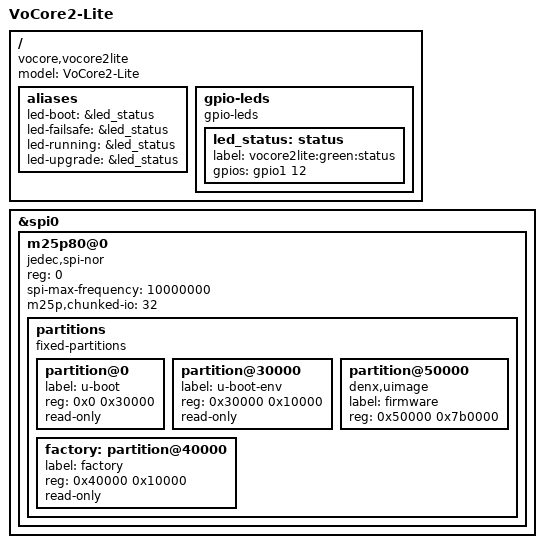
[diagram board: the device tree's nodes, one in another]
/dts-v1/;

#include "VOCORE2.dtsi"

#include <dt-bindings/gpio/gpio.h>

/ {
	compatible = "vocore,vocore2lite", "vocore,vocore2", "mediatek,mt7628an-soc";
	model = "VoCore2-Lite";

	aliases {
		led-boot = &led_status;
		led-failsafe = &led_status;
		led-running = &led_status;
		led-upgrade = &led_status;
	};

	gpio-leds {
		compatible = "gpio-leds";

		led_status: status {
			label = "vocore2lite:green:status";
			gpios = <&gpio1 12 GPIO_ACTIVE_HIGH>;
		};
	};
};

&spi0 {
	status = "okay";

	m25p80@0 {
		compatible = "jedec,spi-nor";
		reg = <0>;
		spi-max-frequency = <10000000>;
		m25p,chunked-io = <32>;

		partitions {
			compatible = "fixed-partitions";
			#address-cells = <1>;
			#size-cells = <1>;

			partition@0 {
				label = "u-boot";
				reg = <0x0 0x30000>;
				read-only;
			};

			partition@30000 {
				label = "u-boot-env";
				reg = <0x30000 0x10000>;
				read-only;
			};

			factory: partition@40000 {
				label = "factory";
				reg = <0x40000 0x10000>;
				read-only;
			};

			partition@50000 {
				compatible = "denx,uimage";
				label = "firmware";
				reg = <0x50000 0x7b0000>;
			};
		};
	};
};
